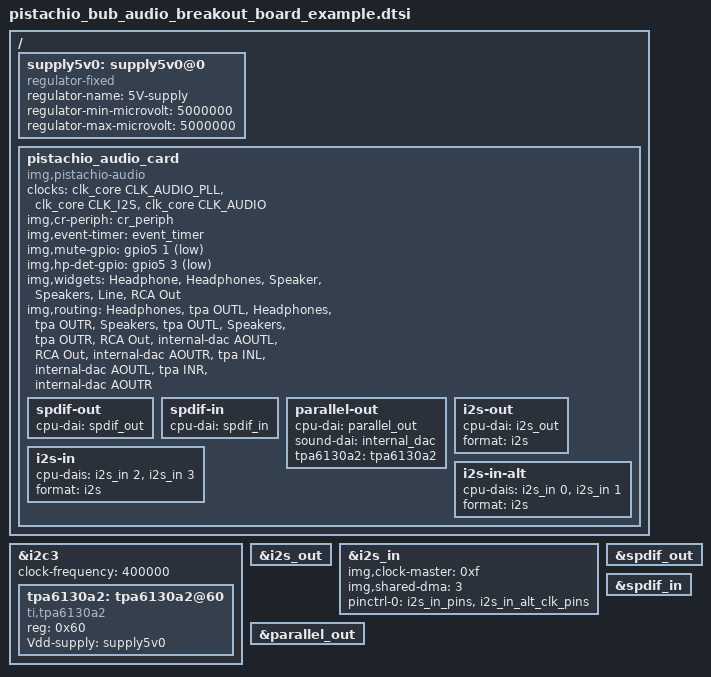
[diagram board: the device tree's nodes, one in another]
/*
 * Copyright (C) 2015 Imagination Technologies Ltd.
 *
 * This program is free software; you can redistribute it and/or modify
 * it under the terms of the GNU General Public License version 2 as
 * published by the Free Software Foundation.
 */

#include "pistachio.dtsi"
#include <dt-bindings/sound/pistachio-audio.h>

/ {
	supply5v0: supply5v0@0 {
		compatible = "regulator-fixed";
		regulator-name = "5V-supply";
		regulator-min-microvolt = <5000000>;
		regulator-max-microvolt = <5000000>;
	};

	pistachio_audio_card {
		compatible = "img,pistachio-audio";

		clocks = <&clk_core CLK_AUDIO_PLL>,
			 <&clk_core CLK_I2S>,
			 <&clk_core CLK_AUDIO>;
		clock-names = "audio_pll", "i2s_mclk", "dac_clk";

		img,cr-periph = <&cr_periph>;
		img,event-timer = <&event_timer>;

		img,mute-gpio = <&gpio5 1 GPIO_ACTIVE_LOW>;
		img,hp-det-gpio = <&gpio5 3 GPIO_ACTIVE_LOW>;

		img,widgets = "Headphone", "Headphones",
			      "Speaker", "Speakers",
			      "Line", "RCA Out";

		img,routing = "Headphones", "tpa OUTL",
			      "Headphones", "tpa OUTR",
			      "Speakers", "tpa OUTL",
			      "Speakers", "tpa OUTR",
			      "RCA Out", "internal-dac AOUTL",
			      "RCA Out", "internal-dac AOUTR",
			      "tpa INL", "internal-dac AOUTL",
			      "tpa INR", "internal-dac AOUTR";

		spdif-out {
			cpu-dai = <&spdif_out>;
		};

		spdif-in {
			cpu-dai = <&spdif_in>;
		};

		parallel-out {
			cpu-dai = <&parallel_out>;
			sound-dai = <&internal_dac>;
			tpa6130a2 = <&tpa6130a2>;
		};

		i2s-out {
			cpu-dai = <&i2s_out>;
			format = "i2s";
		};

		i2s-in {
			cpu-dais = <&i2s_in 2 &i2s_in 3>;
			format = "i2s";
		};

		i2s-in-alt {
			cpu-dais = <&i2s_in 0 &i2s_in 1>;
			format = "i2s";
		};
	};
};

&i2c3 {
	status = "okay";
	clock-frequency = <400000>;

	tpa6130a2: tpa6130a2@60 {
		compatible = "ti,tpa6130a2";
		reg = <0x60>;
		Vdd-supply = <&supply5v0>;
	};
};

&i2s_out {
	status = "okay";
};

&i2s_in {
	status = "okay";
	img,clock-master = <0xf>;
	img,shared-dma = <3>;
	pinctrl-names = "default";
	pinctrl-0 = <&i2s_in_pins>, <&i2s_in_alt_clk_pins>;
};

&spdif_out {
	status = "okay";
};

&spdif_in {
	status = "okay";
};

&parallel_out {
	status = "okay";
};
